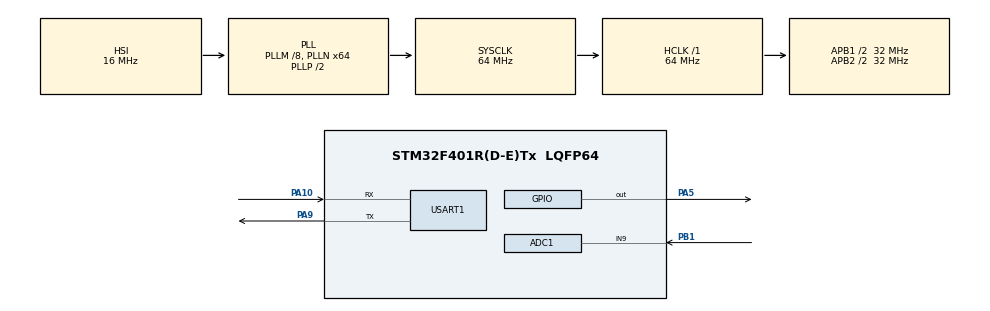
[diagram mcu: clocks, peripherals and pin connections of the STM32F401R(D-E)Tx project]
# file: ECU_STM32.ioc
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ADC1.Channel-0\#ChannelRegularConversion=ADC_CHANNEL_9
ADC1.ContinuousConvMode=ENABLE
ADC1.EOCSelection=ADC_EOC_SEQ_CONV
ADC1.NbrOfConversionFlag=1
ADC1.Rank-0\#ChannelRegularConversion=1
ADC1.SamplingTime-0\#ChannelRegularConversion=ADC_SAMPLETIME_3CYCLES
ADC1.master=1
Mcu.Family=STM32F4
Mcu.Name=STM32F401R(D-E)Tx
Mcu.Package=LQFP64
NVIC.PriorityGroup=NVIC_PRIORITYGROUP_4
PA10.Mode=Asynchronous
PA10.Signal=USART1_RX
PA5.Signal=GPIO_Output
PA9.Mode=Asynchronous
PA9.Signal=USART1_TX
PB1.Signal=ADCx_IN9
ProjectManager.HeapSize=0x200
ProjectManager.StackSize=0x400
ProjectManager.TargetToolchain=STM32CubeIDE
RCC.48MHZClocksFreq_Value=32000000
RCC.AHBFreq_Value=64000000
RCC.APB1CLKDivider=RCC_HCLK_DIV2
RCC.APB1Freq_Value=32000000
RCC.APB1TimFreq_Value=64000000
RCC.APB2CLKDivider=RCC_HCLK_DIV2
RCC.APB2Freq_Value=32000000
RCC.APB2TimFreq_Value=64000000
RCC.CortexFreq_Value=64000000
RCC.HCLKFreq_Value=64000000
RCC.HSE_VALUE=25000000
RCC.HSI_VALUE=16000000
RCC.LSE_VALUE=32768
RCC.PLLM=8
RCC.PLLN=64
RCC.SYSCLKFreq_VALUE=64000000
RCC.SYSCLKSource=RCC_SYSCLKSOURCE_PLLCLK
RCC.VCOOutputFreq_Value=128000000
SH.ADCx_IN9.0=ADC1_IN9,IN9
USART1.VirtualMode=VM_ASYNC
board=custom

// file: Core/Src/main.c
/* USER CODE BEGIN Header */
/**
  ******************************************************************************
  * @file           : main.c
  * @brief          : Main program body
  ******************************************************************************
  * @attention
  *
  * Copyright (c) 2022 STMicroelectronics.
  * All rights reserved.
  *
  * This software is licensed under terms that can be found in the LICENSE file
  * in the root directory of this software component.
  * If no LICENSE file comes with this software, it is provided AS-IS.
  *
  ******************************************************************************
  */
/* USER CODE END Header */
#include "main.h"

ADC_HandleTypeDef hadc1;

UART_HandleTypeDef huart1;

/* USER CODE BEGIN PV */
uint16_t readValue;
float voltage;
/* USER CODE END PV */

void SystemClock_Config(void);
static void MX_GPIO_Init(void);
static void MX_ADC1_Init(void);
static void MX_USART1_UART_Init(void);

int main(void)
{
  /* USER CODE BEGIN 1 */
	uint8_t MSG[35] = {'\0'};
  /* USER CODE END 1 */

  /* MCU Configuration--------------------------------------------------------*/

  /* Reset of all peripherals, Initializes the Flash interface and the Systick. */
  HAL_Init();

  /* Configure the system clock */
  SystemClock_Config();

  /* Initialize all configured peripherals */
  MX_GPIO_Init();
  MX_ADC1_Init();
  MX_USART1_UART_Init();
  /* USER CODE BEGIN 2 */
  HAL_ADC_Start(&hadc1);
  /* USER CODE END 2 */

  /* Infinite loop */
  /* USER CODE BEGIN WHILE */
  while (1)
  {
          //voltage sensor begin code
	      HAL_ADC_PollForConversion(&hadc1,1000);
	      readValue = HAL_ADC_GetValue(&hadc1);
	      voltage =(float)readValue/4095*16.5;
	      //HAL_Delay(100);
	      //voltage sensor End code
         //Led blinking End code
	      /*HAL_GPIO_WritePin (GPIOA, GPIO_PIN_5,1);
	  	  HAL_Delay (1000);
	  	  HAL_GPIO_WritePin (GPIOA, GPIO_PIN_5,0);
	  	  //HAL_Delay (1000);*/
	  	  //Led blinking start code
	  	  //UART code begin
	  	  sprintf(MSG, "%u\r\n", 2);
	  	  HAL_UART_Transmit(&huart1, MSG, sizeof(MSG), 1);
	  	  HAL_Delay(1500);
	  	  //UART code End
    /* USER CODE END WHILE */

  }
}

void SystemClock_Config(void)
{
  RCC_OscInitTypeDef RCC_OscInitStruct = {0};
  RCC_ClkInitTypeDef RCC_ClkInitStruct = {0};

  /** Configure the main internal regulator output voltage
  */
  __HAL_RCC_PWR_CLK_ENABLE();
  __HAL_PWR_VOLTAGESCALING_CONFIG(PWR_REGULATOR_VOLTAGE_SCALE2);

  /** Initializes the RCC Oscillators according to the specified parameters
  * in the RCC_OscInitTypeDef structure.
  */
  RCC_OscInitStruct.OscillatorType = RCC_OSCILLATORTYPE_HSI;
  RCC_OscInitStruct.HSIState = RCC_HSI_ON;
  RCC_OscInitStruct.HSICalibrationValue = RCC_HSICALIBRATION_DEFAULT;
  RCC_OscInitStruct.PLL.PLLState = RCC_PLL_ON;
  RCC_OscInitStruct.PLL.PLLSource = RCC_PLLSOURCE_HSI;
  RCC_OscInitStruct.PLL.PLLM = 8;
  RCC_OscInitStruct.PLL.PLLN = 64;
  RCC_OscInitStruct.PLL.PLLP = RCC_PLLP_DIV2;
  RCC_OscInitStruct.PLL.PLLQ = 4;
  if (HAL_RCC_OscConfig(&RCC_OscInitStruct) != HAL_OK)
  {
    Error_Handler();
  }

  /** Initializes the CPU, AHB and APB buses clocks
  */
  RCC_ClkInitStruct.ClockType = RCC_CLOCKTYPE_HCLK|RCC_CLOCKTYPE_SYSCLK
                              |RCC_CLOCKTYPE_PCLK1|RCC_CLOCKTYPE_PCLK2;
  RCC_ClkInitStruct.SYSCLKSource = RCC_SYSCLKSOURCE_PLLCLK;
  RCC_ClkInitStruct.AHBCLKDivider = RCC_SYSCLK_DIV1;
  RCC_ClkInitStruct.APB1CLKDivider = RCC_HCLK_DIV2;
  RCC_ClkInitStruct.APB2CLKDivider = RCC_HCLK_DIV2;

  if (HAL_RCC_ClockConfig(&RCC_ClkInitStruct, FLASH_LATENCY_2) != HAL_OK)
  {
    Error_Handler();
  }
}

static void MX_ADC1_Init(void)
{

  ADC_ChannelConfTypeDef sConfig = {0};

  /** Configure the global features of the ADC (Clock, Resolution, Data Alignment and number of conversion)
  */
  hadc1.Instance = ADC1;
  hadc1.Init.ClockPrescaler = ADC_CLOCK_SYNC_PCLK_DIV2;
  hadc1.Init.Resolution = ADC_RESOLUTION_12B;
  hadc1.Init.ScanConvMode = DISABLE;
  hadc1.Init.ContinuousConvMode = ENABLE;
  hadc1.Init.DiscontinuousConvMode = DISABLE;
  hadc1.Init.ExternalTrigConvEdge = ADC_EXTERNALTRIGCONVEDGE_NONE;
  hadc1.Init.ExternalTrigConv = ADC_SOFTWARE_START;
  hadc1.Init.DataAlign = ADC_DATAALIGN_RIGHT;
  hadc1.Init.NbrOfConversion = 1;
  hadc1.Init.DMAContinuousRequests = DISABLE;
  hadc1.Init.EOCSelection = ADC_EOC_SEQ_CONV;
  if (HAL_ADC_Init(&hadc1) != HAL_OK)
  {
    Error_Handler();
  }

  /** Configure for the selected ADC regular channel its corresponding rank in the sequencer and its sample time.
  */
  sConfig.Channel = ADC_CHANNEL_9;
  sConfig.Rank = 1;
  sConfig.SamplingTime = ADC_SAMPLETIME_3CYCLES;
  if (HAL_ADC_ConfigChannel(&hadc1, &sConfig) != HAL_OK)
  {
    Error_Handler();
  }

}

static void MX_USART1_UART_Init(void)
{

  huart1.Instance = USART1;
  huart1.Init.BaudRate = 115200;
  huart1.Init.WordLength = UART_WORDLENGTH_8B;
  huart1.Init.StopBits = UART_STOPBITS_1;
  huart1.Init.Parity = UART_PARITY_NONE;
  huart1.Init.Mode = UART_MODE_TX_RX;
  huart1.Init.HwFlowCtl = UART_HWCONTROL_NONE;
  huart1.Init.OverSampling = UART_OVERSAMPLING_16;
  if (HAL_UART_Init(&huart1) != HAL_OK)
  {
    Error_Handler();
  }

}

static void MX_GPIO_Init(void)
{
  GPIO_InitTypeDef GPIO_InitStruct = {0};

  /* GPIO Ports Clock Enable */
  __HAL_RCC_GPIOA_CLK_ENABLE();
  __HAL_RCC_GPIOB_CLK_ENABLE();

  /*Configure GPIO pin Output Level */
  HAL_GPIO_WritePin(GPIOA, GPIO_PIN_5, GPIO_PIN_RESET);

  /*Configure GPIO pin : PA5 */
  GPIO_InitStruct.Pin = GPIO_PIN_5;
  GPIO_InitStruct.Mode = GPIO_MODE_OUTPUT_PP;
  GPIO_InitStruct.Pull = GPIO_NOPULL;
  GPIO_InitStruct.Speed = GPIO_SPEED_FREQ_LOW;
  HAL_GPIO_Init(GPIOA, &GPIO_InitStruct);

}

void Error_Handler(void)
{
  __disable_irq();
  while (1)
  {
  }
}
